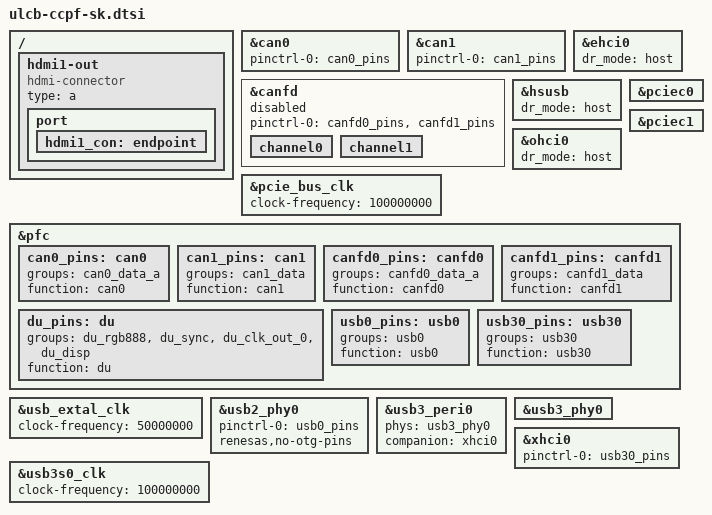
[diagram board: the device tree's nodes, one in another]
// SPDX-License-Identifier: GPL-2.0
/*
 * Device Tree Source for the CCPF (ULCB extension) board
 *
 * Copyright (C) 2021 Renesas Electronics Corp.
 */

#include <dt-bindings/gpio/gpio.h>

/ {
	hdmi1-out {
		compatible = "hdmi-connector";
		type = "a";

		port {
			hdmi1_con: endpoint {
			};
		};
	};
};

&can0 {
	pinctrl-0 = <&can0_pins>;
	pinctrl-names = "default";
	status = "okay";
};

&can1 {
	pinctrl-0 = <&can1_pins>;
	pinctrl-names = "default";
	status = "okay";
};

&canfd {
	pinctrl-0 = <&canfd0_pins &canfd1_pins>;
	pinctrl-names = "default";
	status = "disabled";

	channel0 {
		status = "okay";
	};

	channel1 {
		status = "okay";
	};
};

&ehci0 {
	dr_mode = "host";
	status = "okay";
};

&hsusb {
	dr_mode = "host";
	status = "okay";
};

&ohci0 {
	dr_mode = "host";
	status = "okay";
};

&pcie_bus_clk {
	clock-frequency = <100000000>;
};

&pciec0 {
	status = "okay";
};

&pciec1 {
	status = "okay";
};

&pfc {
	can0_pins: can0 {
		groups = "can0_data_a";
		function = "can0";
	};

	can1_pins: can1 {
		groups = "can1_data";
		function = "can1";
	};

	canfd0_pins: canfd0 {
		groups = "canfd0_data_a";
		function = "canfd0";
	};

	canfd1_pins: canfd1 {
		groups = "canfd1_data";
		function = "canfd1";
	};

	du_pins: du {
		groups = "du_rgb888", "du_sync", "du_clk_out_0", "du_disp";
		function = "du";
	};

	usb0_pins: usb0 {
		groups = "usb0";
		function = "usb0";
	};

	usb30_pins: usb30 {
		groups = "usb30";
		function = "usb30";
	};
};

&usb_extal_clk {
	clock-frequency = <50000000>;
};

&usb2_phy0 {
	pinctrl-0 = <&usb0_pins>;
	pinctrl-names = "default";

	renesas,no-otg-pins;

	status = "okay";
};

&usb3_peri0 {
	phys = <&usb3_phy0>;
	phy-names = "usb";

	companion = <&xhci0>;

	status = "okay";
};

&usb3_phy0 {
	status = "okay";
};

&usb3s0_clk {
	clock-frequency = <100000000>;
};

&xhci0 {
	pinctrl-0 = <&usb30_pins>;
	pinctrl-names = "default";

	status = "okay";
};
